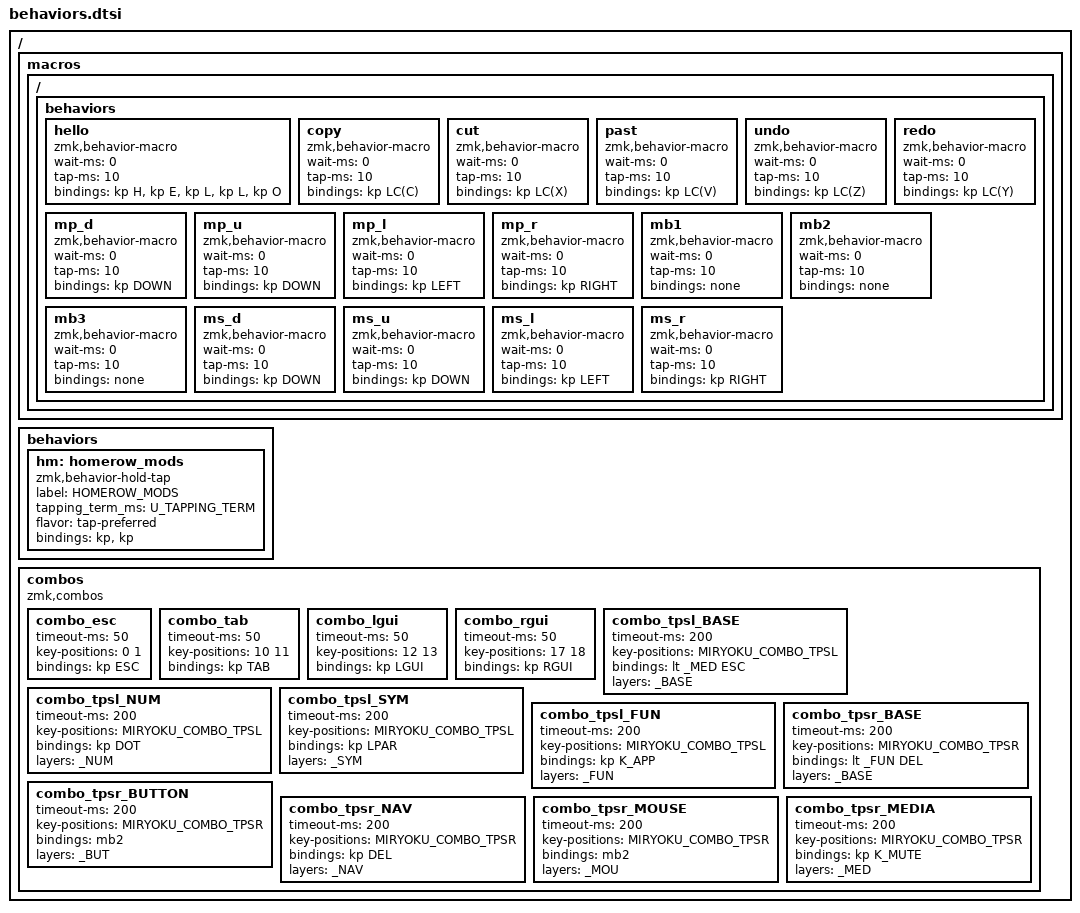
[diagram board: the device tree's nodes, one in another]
#include "constants.dtsi"

/ {

    // macros
    macros {
        ZMK_MACRO(hello,
            wait-ms = <0>;
            tap-ms  = <10>;
            bindings = <&kp H &kp E &kp L &kp L &kp O>;
            )

        ZMK_MACRO(hello,
            wait-ms = <0>;
            tap-ms  = <10>;
            bindings = <&kp H &kp E &kp L &kp L &kp O>;
            )

        ZMK_MACRO(copy,
            wait-ms = <0>;
            tap-ms  = <10>;
            bindings = <&kp LC(C)>;
            )

        ZMK_MACRO(cut,
            wait-ms = <0>;
            tap-ms  = <10>;
            bindings = <&kp LC(X)>;
            )

        ZMK_MACRO(past,
            wait-ms = <0>;
            tap-ms  = <10>;
            bindings = <&kp LC(V)>;
            )

        ZMK_MACRO(undo,
            wait-ms = <0>;
            tap-ms  = <10>;
            bindings = <&kp LC(Z)>;
            )

        ZMK_MACRO(redo,
            wait-ms = <0>;
            tap-ms  = <10>;
            bindings = <&kp LC(Y)>;
            )

        // Mouse move
        ZMK_MACRO(mp_d,
            wait-ms = <0>;
            tap-ms  = <10>;
            bindings = <&kp DOWN>;
            )

        ZMK_MACRO(mp_u,
            wait-ms = <0>;
            tap-ms  = <10>;
            bindings = <&kp DOWN>;
            )

        ZMK_MACRO(mp_l,
            wait-ms = <0>;
            tap-ms  = <10>;
            bindings = <&kp LEFT>;
            )

        ZMK_MACRO(mp_r,
            wait-ms = <0>;
            tap-ms  = <10>;
            bindings = <&kp RIGHT>;
            )

        ZMK_MACRO(mb1,
            wait-ms = <0>;
            tap-ms  = <10>;
            bindings = <&none>;
            )

        ZMK_MACRO(mb2,
            wait-ms = <0>;
            tap-ms  = <10>;
            bindings = <&none>;
            )

        ZMK_MACRO(mb3,
            wait-ms = <0>;
            tap-ms  = <10>;
            bindings = <&none>;
            )
        // Mouse keys
        ZMK_MACRO(ms_d,
            wait-ms = <0>;
            tap-ms  = <10>;
            bindings = <&kp DOWN>;
            )

        ZMK_MACRO(ms_u,
            wait-ms = <0>;
            tap-ms  = <10>;
            bindings = <&kp DOWN>;
            )

        ZMK_MACRO(ms_l,
            wait-ms = <0>;
            tap-ms  = <10>;
            bindings = <&kp LEFT>;
            )

        ZMK_MACRO(ms_r,
            wait-ms = <0>;
            tap-ms  = <10>;
            bindings = <&kp RIGHT>;
            )

    };

    // custom shift using mod-morph
    behaviors {
        hm: homerow_mods {
            compatible = "zmk,behavior-hold-tap";
            label = "HOMEROW_MODS";
            #binding-cells = <2>;
            tapping_term_ms = <U_TAPPING_TERM>;
            flavor = "tap-preferred";
            bindings = <&kp>, <&kp>;
        };
    };

    // combos
    combos {
        compatible = "zmk,combos";

        combo_esc {
            timeout-ms = <50>;
            key-positions = <0 1>;
            bindings = <&kp ESC>;
        };

        combo_tab {
            timeout-ms = <50>;
            key-positions = <10 11>;
            bindings = <&kp TAB>;
        };

        combo_lgui {
            timeout-ms = <50>;
            key-positions = <12 13>;
            bindings = <&kp LGUI>;
        };

        combo_rgui {
            timeout-ms = <50>;
            key-positions = <17 18>;
            bindings = <&kp RGUI>;
        };

        combo_tpsl_BASE {
            timeout-ms = <200>;
            key-positions = <MIRYOKU_COMBO_TPSL>;
            bindings = <&lt _MED ESC>;
            layers = <_BASE>;
        };
        combo_tpsl_NUM {
            timeout-ms = <200>;
            key-positions = <MIRYOKU_COMBO_TPSL>;
            bindings = <&kp DOT>;
            layers = <_NUM>;
        };
        combo_tpsl_SYM {
            timeout-ms = <200>;
            key-positions = <MIRYOKU_COMBO_TPSL>;
            bindings = <&kp LPAR>;
            layers = <_SYM>;
        };
        combo_tpsl_FUN {
            timeout-ms = <200>;
            key-positions = <MIRYOKU_COMBO_TPSL>;
            bindings = <&kp K_APP>;
            layers = <_FUN>;
        };
        combo_tpsr_BASE {
            timeout-ms = <200>;
            key-positions = <MIRYOKU_COMBO_TPSR>;
            bindings = <&lt _FUN DEL>;
            layers = <_BASE>;
        };
        combo_tpsr_BUTTON {
            timeout-ms = <200>;
            key-positions = <MIRYOKU_COMBO_TPSR>;
            bindings = <&mb2>;
            layers = <_BUT>;
        };
        combo_tpsr_NAV {
            timeout-ms = <200>;
            key-positions = <MIRYOKU_COMBO_TPSR>;
            bindings = <&kp DEL>;
            layers = <_NAV>;
        };
        combo_tpsr_MOUSE {
            timeout-ms = <200>;
            key-positions = <MIRYOKU_COMBO_TPSR>;
            bindings = <&mb2>;
            layers = <_MOU>;
        };
        combo_tpsr_MEDIA {
            timeout-ms = <200>;
            key-positions = <MIRYOKU_COMBO_TPSR>;
            bindings = <&kp K_MUTE>;
            layers = <_MED>;
        };
    };
};
